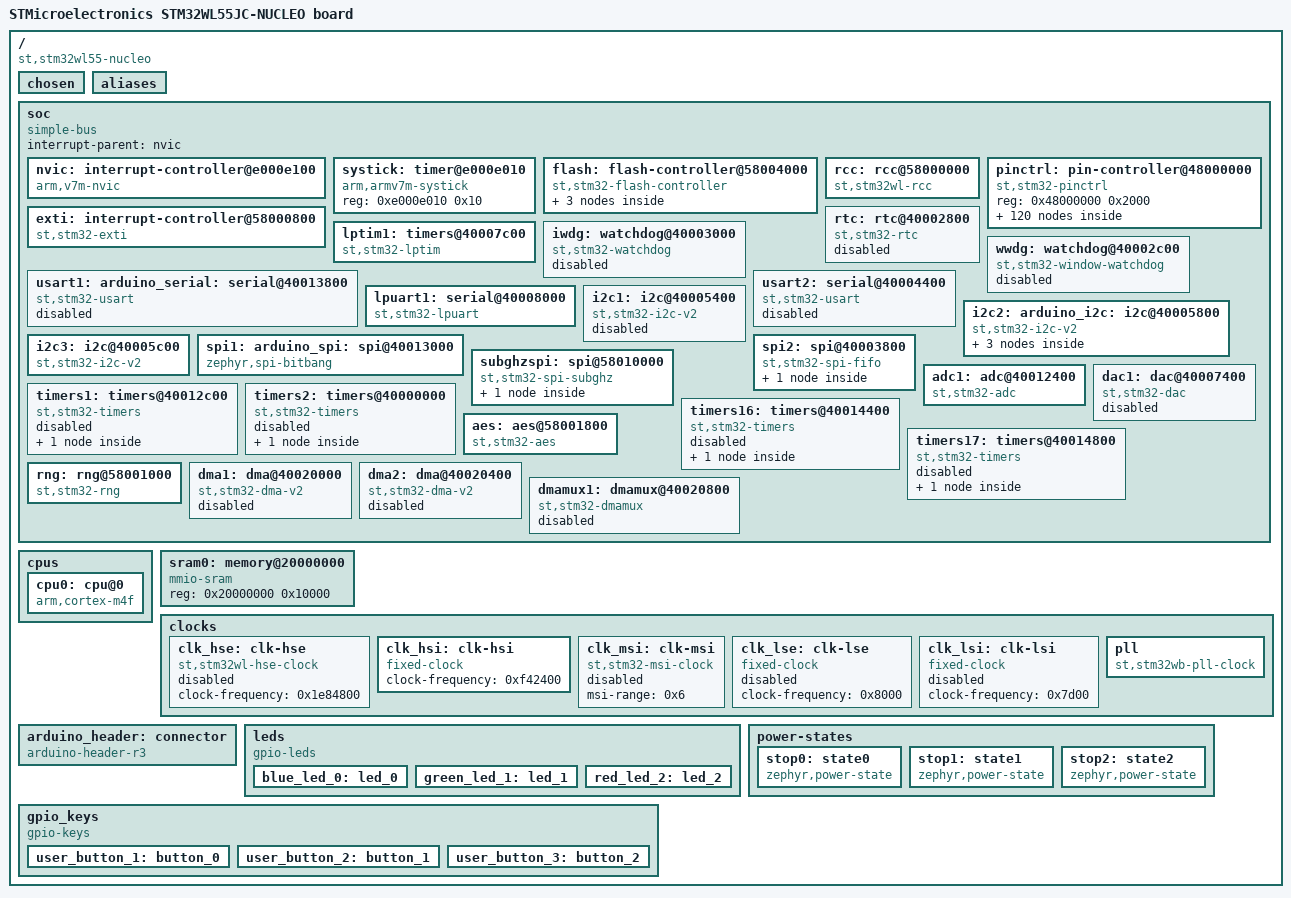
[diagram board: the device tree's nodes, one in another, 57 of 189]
/dts-v1/;

/ {
	#address-cells = < 0x1 >;
	#size-cells = < 0x1 >;
	model = "STMicroelectronics STM32WL55JC-NUCLEO board";
	compatible = "st,stm32wl55-nucleo";
	chosen {
		zephyr,entropy = &rng;
		zephyr,flash-controller = &flash;
		zephyr,console = &lpuart1;
		zephyr,shell-uart = &lpuart1;
		zephyr,sram = &sram0;
		zephyr,flash = &flash0;
		zephyr,code-partition = &flash0;
	};
	aliases {
		led0 = &blue_led_0;
		led1 = &green_led_1;
		led2 = &red_led_2;
		sw0 = &user_button_1;
		sw1 = &user_button_2;
		sw2 = &user_button_3;
		lora0 = &lora;
	};
	soc {
		#address-cells = < 0x1 >;
		#size-cells = < 0x1 >;
		compatible = "simple-bus";
		interrupt-parent = < &nvic >;
		ranges;
		nvic: interrupt-controller@e000e100 {
			#address-cells = < 0x1 >;
			compatible = "arm,v7m-nvic";
			reg = < 0xe000e100 0xc00 >;
			interrupt-controller;
			#interrupt-cells = < 0x2 >;
			arm,num-irq-priority-bits = < 0x4 >;
			phandle = < 0x1 >;
		};
		systick: timer@e000e010 {
			compatible = "arm,armv7m-systick";
			reg = < 0xe000e010 0x10 >;
		};
		flash: flash-controller@58004000 {
			compatible = "st,stm32-flash-controller", "st,stm32wl-flash-controller";
			label = "FLASH_CTRL";
			reg = < 0x58004000 0x400 >;
			interrupts = < 0x4 0x0 >;
			#address-cells = < 0x1 >;
			#size-cells = < 0x1 >;
			flash0: flash@8000000 {
				compatible = "st,stm32-nv-flash", "soc-nv-flash";
				label = "FLASH_STM32";
				write-block-size = < 0x8 >;
				erase-block-size = < 0x800 >;
				max-erase-time = < 0x19 >;
				reg = < 0x8000000 0x40000 >;
				partitions {
					compatible = "fixed-partitions";
					#address-cells = < 0x1 >;
					#size-cells = < 0x1 >;
					storage_partition: partition@3c000 {
						label = "storage";
						reg = < 0x3c000 0x4000 >;
					};
				};
			};
		};
		rcc: rcc@58000000 {
			compatible = "st,stm32wl-rcc";
			#clock-cells = < 0x2 >;
			reg = < 0x58000000 0x400 >;
			label = "STM32_CLK_RCC";
			clocks = < &pll >;
			clock-frequency = < 0x2dc6c00 >;
			cpu1-prescaler = < 0x1 >;
			cpu2-prescaler = < 0x1 >;
			ahb3-prescaler = < 0x1 >;
			apb1-prescaler = < 0x1 >;
			apb2-prescaler = < 0x1 >;
			phandle = < 0x3 >;
		};
		exti: interrupt-controller@58000800 {
			compatible = "st,stm32-exti";
			interrupt-controller;
			#interrupt-cells = < 0x1 >;
			reg = < 0x58000800 0x400 >;
		};
		pinctrl: pin-controller@48000000 {
			compatible = "st,stm32-pinctrl";
			#address-cells = < 0x1 >;
			#size-cells = < 0x1 >;
			reg = < 0x48000000 0x2000 >;
			gpioa: gpio@48000000 {
				compatible = "st,stm32-gpio";
				gpio-controller;
				#gpio-cells = < 0x2 >;
				reg = < 0x48000000 0x400 >;
				clocks = < &rcc 0x1 0x1 >;
				label = "GPIOA";
				phandle = < 0x8 >;
			};
			gpiob: gpio@48000400 {
				compatible = "st,stm32-gpio";
				gpio-controller;
				#gpio-cells = < 0x2 >;
				reg = < 0x48000400 0x400 >;
				clocks = < &rcc 0x1 0x2 >;
				label = "GPIOB";
				phandle = < 0x13 >;
			};
			gpioc: gpio@48000800 {
				compatible = "st,stm32-gpio";
				gpio-controller;
				#gpio-cells = < 0x2 >;
				reg = < 0x48000800 0x400 >;
				clocks = < &rcc 0x1 0x4 >;
				label = "GPIOC";
				phandle = < 0x14 >;
			};
			gpioh: gpio@48001c00 {
				compatible = "st,stm32-gpio";
				gpio-controller;
				#gpio-cells = < 0x2 >;
				reg = < 0x48001c00 0x400 >;
				clocks = < &rcc 0x1 0x80 >;
				label = "GPIOH";
			};
			adc_in6_pa10: adc_in6_pa10 {
				pinmux = < 0x150 >;
			};
			adc_in7_pa11: adc_in7_pa11 {
				pinmux = < 0x170 >;
			};
			adc_in8_pa12: adc_in8_pa12 {
				pinmux = < 0x190 >;
			};
			adc_in9_pa13: adc_in9_pa13 {
				pinmux = < 0x1b0 >;
			};
			adc_in10_pa14: adc_in10_pa14 {
				pinmux = < 0x1d0 >;
			};
			adc_in11_pa15: adc_in11_pa15 {
				pinmux = < 0x1f0 >;
			};
			adc_in5_pb1: adc_in5_pb1 {
				pinmux = < 0x230 >;
				phandle = < 0x15 >;
			};
			adc_in4_pb2: adc_in4_pb2 {
				pinmux = < 0x250 >;
			};
			adc_in2_pb3: adc_in2_pb3 {
				pinmux = < 0x270 >;
			};
			adc_in3_pb4: adc_in3_pb4 {
				pinmux = < 0x290 >;
			};
			adc_in0_pb13: adc_in0_pb13 {
				pinmux = < 0x3b0 >;
			};
			adc_in1_pb14: adc_in1_pb14 {
				pinmux = < 0x3d0 >;
			};
			dac_out1_pa10: dac_out1_pa10 {
				pinmux = < 0x150 >;
			};
			i2c1_scl_pa9: i2c1_scl_pa9 {
				pinmux = < 0x124 >;
				bias-pull-up;
				drive-open-drain;
			};
			i2c1_scl_pb6: i2c1_scl_pb6 {
				pinmux = < 0x2c4 >;
				bias-pull-up;
				drive-open-drain;
			};
			i2c1_scl_pb8: i2c1_scl_pb8 {
				pinmux = < 0x304 >;
				bias-pull-up;
				drive-open-drain;
			};
			i2c2_scl_pa12: i2c2_scl_pa12 {
				pinmux = < 0x184 >;
				bias-pull-up;
				drive-open-drain;
				phandle = < 0x6 >;
			};
			i2c2_scl_pb15: i2c2_scl_pb15 {
				pinmux = < 0x3e4 >;
				bias-pull-up;
				drive-open-drain;
			};
			i2c3_scl_pa7: i2c3_scl_pa7 {
				pinmux = < 0xe4 >;
				bias-pull-up;
				drive-open-drain;
			};
			i2c3_scl_pb10: i2c3_scl_pb10 {
				pinmux = < 0x344 >;
				bias-pull-up;
				drive-open-drain;
				phandle = < 0x9 >;
			};
			i2c3_scl_pb13: i2c3_scl_pb13 {
				pinmux = < 0x3a4 >;
				bias-pull-up;
				drive-open-drain;
			};
			i2c3_scl_pc0: i2c3_scl_pc0 {
				pinmux = < 0x404 >;
				bias-pull-up;
				drive-open-drain;
			};
			i2c1_sda_pa10: i2c1_sda_pa10 {
				pinmux = < 0x144 >;
				bias-pull-up;
				drive-open-drain;
			};
			i2c1_sda_pb7: i2c1_sda_pb7 {
				pinmux = < 0x2e4 >;
				bias-pull-up;
				drive-open-drain;
			};
			i2c1_sda_pb9: i2c1_sda_pb9 {
				pinmux = < 0x324 >;
				bias-pull-up;
				drive-open-drain;
			};
			i2c2_sda_pa11: i2c2_sda_pa11 {
				pinmux = < 0x164 >;
				bias-pull-up;
				drive-open-drain;
				phandle = < 0x7 >;
			};
			i2c2_sda_pa15: i2c2_sda_pa15 {
				pinmux = < 0x1e4 >;
				bias-pull-up;
				drive-open-drain;
			};
			i2c3_sda_pb4: i2c3_sda_pb4 {
				pinmux = < 0x284 >;
				bias-pull-up;
				drive-open-drain;
				phandle = < 0xa >;
			};
			i2c3_sda_pb11: i2c3_sda_pb11 {
				pinmux = < 0x364 >;
				bias-pull-up;
				drive-open-drain;
			};
			i2c3_sda_pb14: i2c3_sda_pb14 {
				pinmux = < 0x3c4 >;
				bias-pull-up;
				drive-open-drain;
			};
			i2c3_sda_pc1: i2c3_sda_pc1 {
				pinmux = < 0x424 >;
				bias-pull-up;
				drive-open-drain;
			};
			i2s2_ck_pa8: i2s2_ck_pa8 {
				pinmux = < 0x105 >;
				slew-rate = "very-high-speed";
			};
			i2s2_ck_pa9: i2s2_ck_pa9 {
				pinmux = < 0x125 >;
				slew-rate = "very-high-speed";
			};
			i2s2_ck_pb10: i2s2_ck_pb10 {
				pinmux = < 0x345 >;
				slew-rate = "very-high-speed";
			};
			i2s2_ck_pb13: i2s2_ck_pb13 {
				pinmux = < 0x3a5 >;
				slew-rate = "very-high-speed";
			};
			i2s2_sd_pa10: i2s2_sd_pa10 {
				pinmux = < 0x145 >;
			};
			i2s2_sd_pb15: i2s2_sd_pb15 {
				pinmux = < 0x3e5 >;
			};
			i2s2_sd_pc1: i2s2_sd_pc1 {
				pinmux = < 0x423 >;
			};
			i2s2_sd_pc3: i2s2_sd_pc3 {
				pinmux = < 0x465 >;
			};
			i2s2_ws_pa9: i2s2_ws_pa9 {
				pinmux = < 0x123 >;
			};
			i2s2_ws_pb9: i2s2_ws_pb9 {
				pinmux = < 0x325 >;
			};
			i2s2_ws_pb12: i2s2_ws_pb12 {
				pinmux = < 0x385 >;
			};
			spi1_miso_pa6: spi1_miso_pa6 {
				pinmux = < 0xc5 >;
				bias-pull-down;
				phandle = < 0xd >;
			};
			spi1_miso_pa11: spi1_miso_pa11 {
				pinmux = < 0x165 >;
				bias-pull-down;
			};
			spi1_miso_pb4: spi1_miso_pb4 {
				pinmux = < 0x285 >;
				bias-pull-down;
			};
			spi2_miso_pa5: spi2_miso_pa5 {
				pinmux = < 0xa3 >;
				bias-pull-down;
			};
			spi2_miso_pb14: spi2_miso_pb14 {
				pinmux = < 0x3c5 >;
				bias-pull-down;
				phandle = < 0x11 >;
			};
			spi2_miso_pc2: spi2_miso_pc2 {
				pinmux = < 0x445 >;
				bias-pull-down;
			};
			spi1_mosi_pa7: spi1_mosi_pa7 {
				pinmux = < 0xe5 >;
				bias-pull-down;
				phandle = < 0xe >;
			};
			spi1_mosi_pa12: spi1_mosi_pa12 {
				pinmux = < 0x185 >;
				bias-pull-down;
			};
			spi1_mosi_pb5: spi1_mosi_pb5 {
				pinmux = < 0x2a5 >;
				bias-pull-down;
			};
			spi2_mosi_pa10: spi2_mosi_pa10 {
				pinmux = < 0x145 >;
				bias-pull-down;
			};
			spi2_mosi_pb15: spi2_mosi_pb15 {
				pinmux = < 0x3e5 >;
				bias-pull-down;
				phandle = < 0x12 >;
			};
			spi2_mosi_pc1: spi2_mosi_pc1 {
				pinmux = < 0x423 >;
				bias-pull-down;
			};
			spi2_mosi_pc3: spi2_mosi_pc3 {
				pinmux = < 0x465 >;
				bias-pull-down;
			};
			spi1_nss_pa4: spi1_nss_pa4 {
				pinmux = < 0x85 >;
				bias-pull-up;
				phandle = < 0xb >;
			};
			spi1_nss_pa15: spi1_nss_pa15 {
				pinmux = < 0x1e5 >;
				bias-pull-up;
			};
			spi1_nss_pb2: spi1_nss_pb2 {
				pinmux = < 0x245 >;
				bias-pull-up;
			};
			spi2_nss_pa9: spi2_nss_pa9 {
				pinmux = < 0x123 >;
				bias-pull-up;
			};
			spi2_nss_pb9: spi2_nss_pb9 {
				pinmux = < 0x325 >;
				bias-pull-up;
			};
			spi2_nss_pb12: spi2_nss_pb12 {
				pinmux = < 0x385 >;
				bias-pull-up;
				phandle = < 0xf >;
			};
			spi1_sck_pa1: spi1_sck_pa1 {
				pinmux = < 0x25 >;
				bias-pull-down;
				slew-rate = "very-high-speed";
			};
			spi1_sck_pa5: spi1_sck_pa5 {
				pinmux = < 0xa5 >;
				bias-pull-down;
				slew-rate = "very-high-speed";
				phandle = < 0xc >;
			};
			spi1_sck_pb3: spi1_sck_pb3 {
				pinmux = < 0x265 >;
				bias-pull-down;
				slew-rate = "very-high-speed";
			};
			spi2_sck_pa8: spi2_sck_pa8 {
				pinmux = < 0x105 >;
				bias-pull-down;
				slew-rate = "very-high-speed";
			};
			spi2_sck_pa9: spi2_sck_pa9 {
				pinmux = < 0x125 >;
				bias-pull-down;
				slew-rate = "very-high-speed";
			};
			spi2_sck_pb10: spi2_sck_pb10 {
				pinmux = < 0x345 >;
				bias-pull-down;
				slew-rate = "very-high-speed";
			};
			spi2_sck_pb13: spi2_sck_pb13 {
				pinmux = < 0x3a5 >;
				bias-pull-down;
				slew-rate = "very-high-speed";
				phandle = < 0x10 >;
			};
			tim1_ch1n_pa7: tim1_ch1n_pa7 {
				pinmux = < 0xe1 >;
			};
			tim1_ch1_pa8: tim1_ch1_pa8 {
				pinmux = < 0x101 >;
			};
			tim1_ch2_pa9: tim1_ch2_pa9 {
				pinmux = < 0x121 >;
			};
			tim1_ch3_pa10: tim1_ch3_pa10 {
				pinmux = < 0x141 >;
			};
			tim1_ch4_pa11: tim1_ch4_pa11 {
				pinmux = < 0x161 >;
			};
			tim1_ch2n_pb8: tim1_ch2n_pb8 {
				pinmux = < 0x301 >;
			};
			tim1_ch3n_pb9: tim1_ch3n_pb9 {
				pinmux = < 0x321 >;
			};
			tim1_ch1n_pb13: tim1_ch1n_pb13 {
				pinmux = < 0x3a1 >;
			};
			tim1_ch2n_pb14: tim1_ch2n_pb14 {
				pinmux = < 0x3c1 >;
			};
			tim1_ch3n_pb15: tim1_ch3n_pb15 {
				pinmux = < 0x3e1 >;
			};
			tim2_ch1_pa0: tim2_ch1_pa0 {
				pinmux = < 0x1 >;
			};
			tim2_ch2_pa1: tim2_ch2_pa1 {
				pinmux = < 0x21 >;
			};
			tim2_ch3_pa2: tim2_ch3_pa2 {
				pinmux = < 0x41 >;
			};
			tim2_ch4_pa3: tim2_ch4_pa3 {
				pinmux = < 0x61 >;
			};
			tim2_ch1_pa5: tim2_ch1_pa5 {
				pinmux = < 0xa1 >;
			};
			tim2_ch1_pa15: tim2_ch1_pa15 {
				pinmux = < 0x1e1 >;
			};
			tim2_ch2_pb3: tim2_ch2_pb3 {
				pinmux = < 0x261 >;
			};
			tim2_ch3_pb10: tim2_ch3_pb10 {
				pinmux = < 0x341 >;
			};
			tim2_ch4_pb11: tim2_ch4_pb11 {
				pinmux = < 0x361 >;
			};
			tim16_ch1_pa6: tim16_ch1_pa6 {
				pinmux = < 0xce >;
			};
			tim16_ch1n_pb6: tim16_ch1n_pb6 {
				pinmux = < 0x2ce >;
			};
			tim16_ch1_pb8: tim16_ch1_pb8 {
				pinmux = < 0x30e >;
			};
			tim17_ch1_pa7: tim17_ch1_pa7 {
				pinmux = < 0xee >;
			};
			tim17_ch1n_pb7: tim17_ch1n_pb7 {
				pinmux = < 0x2ee >;
			};
			tim17_ch1_pb9: tim17_ch1_pb9 {
				pinmux = < 0x32e >;
			};
			lpuart1_cts_pa6: lpuart1_cts_pa6 {
				pinmux = < 0xc8 >;
				bias-pull-up;
				drive-open-drain;
			};
			usart1_cts_pa11: usart1_cts_pa11 {
				pinmux = < 0x167 >;
				bias-pull-up;
				drive-open-drain;
			};
			usart1_cts_pb4: usart1_cts_pb4 {
				pinmux = < 0x287 >;
				bias-pull-up;
				drive-open-drain;
			};
			lpuart1_cts_pb13: lpuart1_cts_pb13 {
				pinmux = < 0x3a8 >;
				bias-pull-up;
				drive-open-drain;
			};
			usart2_cts_pa0: usart2_cts_pa0 {
				pinmux = < 0x7 >;
				bias-pull-up;
				drive-open-drain;
			};
			lpuart1_rts_pa1: lpuart1_rts_pa1 {
				pinmux = < 0x28 >;
				bias-pull-up;
				drive-open-drain;
			};
			usart1_rts_pa12: usart1_rts_pa12 {
				pinmux = < 0x187 >;
				bias-pull-up;
				drive-open-drain;
			};
			lpuart1_rts_pb1: lpuart1_rts_pb1 {
				pinmux = < 0x228 >;
				bias-pull-up;
				drive-open-drain;
			};
			usart1_rts_pb3: usart1_rts_pb3 {
				pinmux = < 0x267 >;
				bias-pull-up;
				drive-open-drain;
			};
			lpuart1_rts_pb12: lpuart1_rts_pb12 {
				pinmux = < 0x388 >;
				bias-pull-up;
				drive-open-drain;
			};
			usart2_rts_pa1: usart2_rts_pa1 {
				pinmux = < 0x27 >;
				bias-pull-up;
				drive-open-drain;
			};
			lpuart1_rx_pa3: lpuart1_rx_pa3 {
				pinmux = < 0x68 >;
				phandle = < 0x5 >;
			};
			usart1_rx_pa10: usart1_rx_pa10 {
				pinmux = < 0x147 >;
			};
			usart1_rx_pb7: usart1_rx_pb7 {
				pinmux = < 0x2e7 >;
			};
			lpuart1_rx_pb10: lpuart1_rx_pb10 {
				pinmux = < 0x348 >;
			};
			lpuart1_rx_pc0: lpuart1_rx_pc0 {
				pinmux = < 0x408 >;
			};
			usart2_rx_pa3: usart2_rx_pa3 {
				pinmux = < 0x67 >;
			};
			lpuart1_tx_pa2: lpuart1_tx_pa2 {
				pinmux = < 0x48 >;
				bias-pull-up;
				phandle = < 0x4 >;
			};
			usart1_tx_pa9: usart1_tx_pa9 {
				pinmux = < 0x127 >;
				bias-pull-up;
			};
			usart1_tx_pb6: usart1_tx_pb6 {
				pinmux = < 0x2c7 >;
				bias-pull-up;
			};
			lpuart1_tx_pb11: lpuart1_tx_pb11 {
				pinmux = < 0x368 >;
				bias-pull-up;
			};
			lpuart1_tx_pc1: lpuart1_tx_pc1 {
				pinmux = < 0x428 >;
				bias-pull-up;
			};
			usart2_tx_pa2: usart2_tx_pa2 {
				pinmux = < 0x47 >;
				bias-pull-up;
			};
		};
		lptim1: timers@40007c00 {
			compatible = "st,stm32-lptim";
			clocks = < &rcc 0x2 0x80000000 >;
			#address-cells = < 0x1 >;
			#size-cells = < 0x0 >;
			reg = < 0x40007c00 0x400 >;
			interrupts = < 0x27 0x1 >;
			interrupt-names = "wakeup";
			status = "okay";
			label = "LPTIM_1";
		};
		rtc: rtc@40002800 {
			compatible = "st,stm32-rtc";
			reg = < 0x40002800 0x400 >;
			interrupts = < 0x2a 0x0 >;
			clocks = < &rcc 0x2 0x400 >;
			prescaler = < 0x8000 >;
			status = "disabled";
			label = "RTC_0";
		};
		iwdg: watchdog@40003000 {
			compatible = "st,stm32-watchdog";
			reg = < 0x40003000 0x400 >;
			label = "IWDG";
			status = "disabled";
		};
		wwdg: watchdog@40002c00 {
			compatible = "st,stm32-window-watchdog";
			reg = < 0x40002c00 0x400 >;
			clocks = < &rcc 0x2 0x800 >;
			label = "WWDG";
			interrupts = < 0x0 0x7 >;
			status = "disabled";
		};
		usart1: arduino_serial: serial@40013800 {
			compatible = "st,stm32-usart", "st,stm32-uart";
			reg = < 0x40013800 0x400 >;
			clocks = < &rcc 0x3 0x4000 >;
			interrupts = < 0x24 0x0 >;
			status = "disabled";
			label = "UART_1";
		};
		usart2: serial@40004400 {
			compatible = "st,stm32-usart", "st,stm32-uart";
			reg = < 0x40004400 0x400 >;
			clocks = < &rcc 0x2 0x20000 >;
			interrupts = < 0x25 0x0 >;
			status = "disabled";
			label = "UART_2";
		};
		lpuart1: serial@40008000 {
			compatible = "st,stm32-lpuart", "st,stm32-uart";
			reg = < 0x40008000 0x400 >;
			clocks = < &rcc 0x4 0x1 >;
			interrupts = < 0x26 0x0 >;
			status = "okay";
			label = "LPUART_1";
			pinctrl-0 = < &lpuart1_tx_pa2 &lpuart1_rx_pa3 >;
			pinctrl-names = "default";
			current-speed = < 0x1c200 >;
		};
		i2c1: i2c@40005400 {
			compatible = "st,stm32-i2c-v2";
			clock-frequency = < 0x186a0 >;
			#address-cells = < 0x1 >;
			#size-cells = < 0x0 >;
			reg = < 0x40005400 0x400 >;
			clocks = < &rcc 0x2 0x200000 >;
			interrupts = < 0x1e 0x0 >, < 0x1f 0x0 >;
			interrupt-names = "event", "error";
			status = "disabled";
			label = "I2C_1";
		};
		i2c2: arduino_i2c: i2c@40005800 {
			compatible = "st,stm32-i2c-v2";
			clock-frequency = < 0x61a80 >;
			#address-cells = < 0x1 >;
			#size-cells = < 0x0 >;
			reg = < 0x40005800 0x400 >;
			clocks = < &rcc 0x2 0x400000 >;
			interrupts = < 0x20 0x0 >, < 0x21 0x0 >;
			interrupt-names = "event", "error";
			status = "okay";
			label = "I2C_2";
			pinctrl-0 = < &i2c2_scl_pa12 &i2c2_sda_pa11 >;
			pinctrl-names = "default";
			sht3xd@44 {
				compatible = "sensirion,sht3xd";
				reg = < 0x44 >;
				label = "SHT3XD";
				alert-gpios = < &gpioa 0x9 0x0 >;
			};
			bme280: bme280@77 {
				compatible = "bosch,bme280";
				reg = < 0x77 >;
				label = "BME280";
			};
			ds3231: ds3231@68 {
				compatible = "maxim,ds3231";
				reg = < 0x68 >;
				label = "DS3231";
			};
		};
		i2c3: i2c@40005c00 {
			compatible = "st,stm32-i2c-v2";
			clock-frequency = < 0x61a80 >;
			#address-cells = < 0x1 >;
			#size-cells = < 0x0 >;
			reg = < 0x40005c00 0x400 >;
			clocks = < &rcc 0x2 0x800000 >;
			interrupts = < 0x30 0x0 >, < 0x31 0x0 >;
			interrupt-names = "event", "error";
			status = "okay";
			label = "I2C_3";
			pinctrl-names = "default";
			pinctrl-0 = < &i2c3_scl_pb10 &i2c3_sda_pb4 >;
		};
		spi1: arduino_spi: spi@40013000 {
			compatible = "zephyr,spi-bitbang";
			#address-cells = < 0x1 >;
			#size-cells = < 0x0 >;
			reg = < 0x40013000 0x400 >;
			interrupts = < 0x22 0x5 >;
			clocks = < &rcc 0x3 0x1000 >;
			status = "okay";
			label = "OPC";
			pinctrl-0 = < &spi1_nss_pa4 &spi1_sck_pa5 &spi1_miso_pa6 &spi1_mosi_pa7 >;
			pinctrl-names = "default";
			clk-gpios = < &gpioa 0x5 0x0 >;
			mosi-gpios = < &gpioa 0x7 0x0 >;
			miso-gpios = < &gpioa 0x6 0x0 >;
			cs-gpios = < &gpioa 0x4 0x1 >;
		};
		spi2: spi@40003800 {
			compatible = "st,stm32-spi-fifo", "st,stm32-spi";
			#address-cells = < 0x1 >;
			#size-cells = < 0x0 >;
			reg = < 0x40003800 0x400 >;
			interrupts = < 0x23 0x5 >;
			clocks = < &rcc 0x2 0x4000 >;
			status = "okay";
			label = "SPI_2";
			pinctrl-names = "default";
			pinctrl-0 = < &spi2_nss_pb12 &spi2_sck_pb13 &spi2_miso_pb14 &spi2_mosi_pb15 >;
			cs-gpios = < &gpiob 0xc 0x1 >;
			sdhc0: sdhc@0 {
				compatible = "zephyr,mmc-spi-slot";
				reg = < 0x0 >;
				status = "okay";
				label = "SDHC0";
				spi-max-frequency = < 0x1312d00 >;
			};
		};
		subghzspi: spi@58010000 {
			compatible = "st,stm32-spi-subghz", "st,stm32-spi-fifo", "st,stm32-spi";
			#address-cells = < 0x1 >;
			#size-cells = < 0x0 >;
			reg = < 0x58010000 0x400 >;
			interrupts = < 0x2c 0x5 >;
			clocks = < &rcc 0xa 0x1 >;
			status = "okay";
			label = "SUBGHZSPI";
			use-subghzspi-nss;
			lora: radio@0 {
				compatible = "st,stm32wl-subghz-radio";
				reg = < 0x0 >;
				interrupts = < 0x32 0x0 >;
				spi-max-frequency = < 0xb71b00 >;
				status = "okay";
				label = "subghz-radio";
				tx-enable-gpios = < &gpioc 0x4 0x1 >;
				rx-enable-gpios = < &gpioc 0x5 0x1 >;
				dio3-tcxo-voltage = < 0x1 >;
				tcxo-power-startup-delay-ms = < 0x5 >;
			};
		};
		adc1: adc@40012400 {
			compatible = "st,stm32-adc";
			reg = < 0x40012400 0x400 >;
			clocks = < &rcc 0x3 0x200 >;
			interrupts = < 0x12 0x0 >;
			status = "okay";
			label = "ADC_1";
			#io-channel-cells = < 0x1 >;
			has-temp-channel;
			has-vref-channel;
			pinctrl-0 = < &adc_in5_pb1 >;
			pinctrl-names = "default";
		};
		dac1: dac@40007400 {
			compatible = "st,stm32-dac";
			reg = < 0x40007400 0x400 >;
			clocks = < &rcc 0x2 0x20000000 >;
			status = "disabled";
			label = "DAC_1";
			#io-channel-cells = < 0x1 >;
		};
		timers1: timers@40012c00 {
			compatible = "st,stm32-timers";
			reg = < 0x40012c00 0x400 >;
			clocks = < &rcc 0x3 0x800 >;
			interrupts = < 0x17 0x0 >, < 0x18 0x0 >, < 0x19 0x0 >, < 0x1a 0x0 >;
			interrupt-names = "brk", "up", "trgcom", "cc";
			st,prescaler = < 0x0 >;
			status = "disabled";
			label = "TIMERS_1";
			pwm {
				compatible = "st,stm32-pwm";
				status = "disabled";
				label = "PWM_1";
				#pwm-cells = < 0x3 >;
			};
		};
		timers2: timers@40000000 {
			compatible = "st,stm32-timers";
			reg = < 0x40000000 0x400 >;
			clocks = < &rcc 0x2 0x1 >;
			interrupts = < 0x1b 0x0 >;
			interrupt-names = "global";
			st,prescaler = < 0x0 >;
			status = "disabled";
			label = "TIMERS_2";
			pwm {
				compatible = "st,stm32-pwm";
				status = "disabled";
				label = "PWM_2";
				#pwm-cells = < 0x3 >;
			};
		};
		timers16: timers@40014400 {
			compatible = "st,stm32-timers";
			reg = < 0x40014400 0x400 >;
			clocks = < &rcc 0x3 0x20000 >;
			interrupts = < 0x1c 0x0 >;
			interrupt-names = "global";
			st,prescaler = < 0x0 >;
			status = "disabled";
			label = "TIMERS_16";
			pwm {
				compatible = "st,stm32-pwm";
				status = "disabled";
				label = "PWM_16";
				#pwm-cells = < 0x3 >;
			};
		};
		timers17: timers@40014800 {
			compatible = "st,stm32-timers";
			reg = < 0x40014800 0x400 >;
			clocks = < &rcc 0x3 0x40000 >;
			interrupts = < 0x1d 0x0 >;
			interrupt-names = "global";
			st,prescaler = < 0x0 >;
			status = "disabled";
			label = "TIMERS_17";
			pwm {
				compatible = "st,stm32-pwm";
				status = "disabled";
				label = "PWM_17";
				#pwm-cells = < 0x3 >;
			};
		};
		aes: aes@58001800 {
			compatible = "st,stm32-aes";
			reg = < 0x58001800 0x400 >;
			clocks = < &rcc 0x6 0x20000 >;
			interrupts = < 0x33 0x0 >;
			status = "okay";
			label = "AES";
		};
		rng: rng@58001000 {
			compatible = "st,stm32-rng";
			reg = < 0x58001000 0x400 >;
			interrupts = < 0x34 0x0 >;
			clocks = < &rcc 0x6 0x40000 >;
			health-test-magic = < 0x17590abc >;
			health-test-config = < 0xaa74 >;
			status = "okay";
			label = "RNG";
		};
		dma1: dma@40020000 {
			compatible = "st,stm32-dma-v2";
			#dma-cells = < 0x3 >;
			reg = < 0x40020000 0x400 >;
			interrupts = < 0xb 0x0 0xc 0x0 0xd 0x0 0xe 0x0 0xf 0x0 0x10 0x0 0x11 0x0 >;
			clocks = < &rcc 0x0 0x1 >;
			dma-requests = < 0x7 >;
			dma-offset = < 0x0 >;
			status = "disabled";
			label = "DMA_1";
		};
		dma2: dma@40020400 {
			compatible = "st,stm32-dma-v2";
			#dma-cells = < 0x3 >;
			reg = < 0x40020400 0x400 >;
			interrupts = < 0x36 0x0 0x37 0x0 0x38 0x0 0x39 0x0 0x3a 0x0 0x3b 0x0 0x3c 0x0 >;
			clocks = < &rcc 0x0 0x2 >;
			dma-requests = < 0x7 >;
			dma-offset = < 0x7 >;
			status = "disabled";
			label = "DMA_2";
		};
		dmamux1: dmamux@40020800 {
			compatible = "st,stm32-dmamux";
			#dma-cells = < 0x3 >;
			reg = < 0x40020800 0x400 >;
			interrupts = < 0x3d 0x0 >;
			clocks = < &rcc 0x0 0x4 >;
			dma-channels = < 0xe >;
			dma-generators = < 0x4 >;
			dma-requests = < 0x26 >;
			status = "disabled";
			label = "DMAMUX_1";
		};
	};
	cpus {
		#address-cells = < 0x1 >;
		#size-cells = < 0x0 >;
		cpu0: cpu@0 {
			device_type = "cpu";
			compatible = "arm,cortex-m4f";
			reg = < 0x0 >;
			cpu-power-states = < &stop0 &stop1 &stop2 >;
		};
	};
	sram0: memory@20000000 {
		compatible = "mmio-sram";
		reg = < 0x20000000 0x10000 >;
	};
	clocks {
		clk_hse: clk-hse {
			#clock-cells = < 0x0 >;
			compatible = "st,stm32wl-hse-clock";
			clock-frequency = < 0x1e84800 >;
			status = "disabled";
		};
		clk_hsi: clk-hsi {
			#clock-cells = < 0x0 >;
			compatible = "fixed-clock";
			clock-frequency = < 0xf42400 >;
			status = "okay";
			phandle = < 0x19 >;
		};
		clk_msi: clk-msi {
			#clock-cells = < 0x0 >;
			compatible = "st,stm32-msi-clock";
			msi-range = < 0x6 >;
			status = "disabled";
		};
		clk_lse: clk-lse {
			#clock-cells = < 0x0 >;
			compatible = "fixed-clock";
			clock-frequency = < 0x8000 >;
			status = "disabled";
		};
		clk_lsi: clk-lsi {
			#clock-cells = < 0x0 >;
			compatible = "fixed-clock";
			clock-frequency = < 0x7d00 >;
			status = "disabled";
		};
		pll: pll {
			#clock-cells = < 0x0 >;
			compatible = "st,stm32wb-pll-clock";
			status = "okay";
			div-m = < 0x1 >;
			mul-n = < 0x6 >;
			div-r = < 0x2 >;
			div-q = < 0x2 >;
			clocks = < &clk_hsi >;
			phandle = < 0x2 >;
		};
	};
	arduino_header: connector {
		compatible = "arduino-header-r3";
		#gpio-cells = < 0x2 >;
		gpio-map-mask = < 0xffffffff 0xffffffc0 >;
		gpio-map-pass-thru = < 0x0 0x3f >;
		gpio-map = < 0x0 0x0 &gpiob 0x1 0x0 >, < 0x1 0x0 &gpiob 0x2 0x0 >, < 0x2 0x0 &gpioa 0xa 0x0 >, < 0x3 0x0 &gpiob 0x4 0x0 >, < 0x4 0x0 &gpiob 0xe 0x0 >, < 0x5 0x0 &gpiob 0xd 0x0 >, < 0x6 0x0 &gpiob 0x7 0x0 >, < 0x7 0x0 &gpiob 0x6 0x0 >, < 0x8 0x0 &gpiob 0xc 0x0 >, < 0x9 0x0 &gpiob 0x3 0x0 >, < 0xa 0x0 &gpiob 0x5 0x0 >, < 0xb 0x0 &gpiob 0x8 0x0 >, < 0xc 0x0 &gpiob 0xa 0x0 >, < 0xd 0x0 &gpioc 0x1 0x0 >, < 0xe 0x0 &gpioc 0x2 0x0 >, < 0xf 0x0 &gpioa 0x9 0x0 >, < 0x10 0x0 &gpioa 0x4 0x0 >, < 0x11 0x0 &gpioa 0x7 0x0 >, < 0x12 0x0 &gpioa 0x6 0x0 >, < 0x13 0x0 &gpioa 0x5 0x0 >, < 0x14 0x0 &gpiob 0xb 0x0 >, < 0x15 0x0 &gpiob 0xc 0x0 >;
	};
	leds {
		compatible = "gpio-leds";
		blue_led_0: led_0 {
			gpios = < &gpiob 0xf 0x0 >;
			label = "User LED1 BLUE";
		};
		green_led_1: led_1 {
			gpios = < &gpiob 0x9 0x0 >;
			label = "User LED2 GREEN";
		};
		red_led_2: led_2 {
			gpios = < &gpiob 0xb 0x0 >;
			label = "User LED3 RED";
		};
	};
	gpio_keys {
		compatible = "gpio-keys";
		user_button_1: button_0 {
			label = "SW1";
			gpios = < &gpioa 0x0 0x11 >;
		};
		user_button_2: button_1 {
			label = "SW2";
			gpios = < &gpioa 0x1 0x11 >;
		};
		user_button_3: button_2 {
			label = "SW3";
			gpios = < &gpioc 0x6 0x11 >;
		};
	};
	power-states {
		stop0: state0 {
			compatible = "zephyr,power-state";
			power-state-name = "suspend-to-idle";
			substate-id = < 0x1 >;
			min-residency-us = < 0x64 >;
			phandle = < 0x16 >;
		};
		stop1: state1 {
			compatible = "zephyr,power-state";
			power-state-name = "suspend-to-idle";
			substate-id = < 0x2 >;
			min-residency-us = < 0x1f4 >;
			phandle = < 0x17 >;
		};
		stop2: state2 {
			compatible = "zephyr,power-state";
			power-state-name = "suspend-to-idle";
			substate-id = < 0x3 >;
			min-residency-us = < 0x384 >;
			phandle = < 0x18 >;
		};
	};
};
